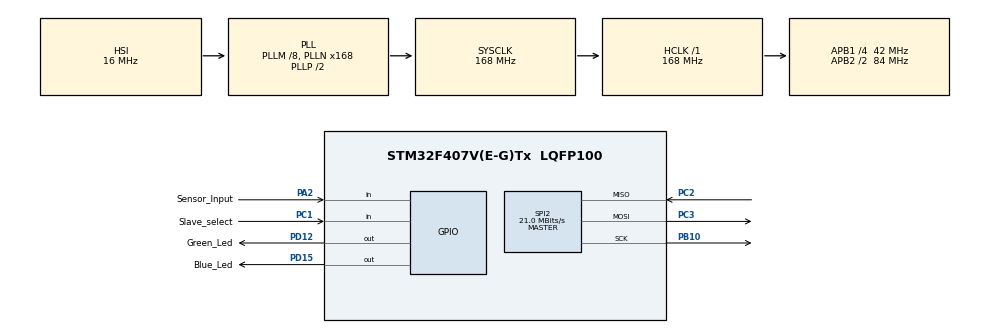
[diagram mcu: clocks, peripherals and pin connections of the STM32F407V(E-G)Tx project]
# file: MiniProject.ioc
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Mcu.Family=STM32F4
Mcu.Name=STM32F407V(E-G)Tx
Mcu.Package=LQFP100
NVIC.PriorityGroup=NVIC_PRIORITYGROUP_0
PA2.GPIO_Label=Sensor_Input
PA2.Signal=GPIO_Input
PB10.Mode=Full_Duplex_Master
PB10.Signal=SPI2_SCK
PC1.GPIO_Label=Slave_select
PC1.Signal=GPIO_Input
PC2.Mode=Full_Duplex_Master
PC2.Signal=SPI2_MISO
PC3.Mode=Full_Duplex_Master
PC3.Signal=SPI2_MOSI
PD12.GPIO_Label=Green_Led
PD12.Signal=GPIO_Output
PD15.GPIO_Label=Blue_Led
PD15.Signal=GPIO_Output
ProjectManager.HeapSize=0x200
ProjectManager.StackSize=0x400
ProjectManager.TargetToolchain=STM32CubeIDE
RCC.48MHZClocksFreq_Value=48000000
RCC.AHBFreq_Value=168000000
RCC.APB1CLKDivider=RCC_HCLK_DIV4
RCC.APB1Freq_Value=42000000
RCC.APB1TimFreq_Value=84000000
RCC.APB2CLKDivider=RCC_HCLK_DIV2
RCC.APB2Freq_Value=84000000
RCC.APB2TimFreq_Value=168000000
RCC.CortexFreq_Value=168000000
RCC.HCLKFreq_Value=168000000
RCC.HSE_VALUE=8000000
RCC.HSI_VALUE=16000000
RCC.PLLM=8
RCC.PLLN=168
RCC.PLLQ=7
RCC.SYSCLKFreq_VALUE=168000000
RCC.SYSCLKSource=RCC_SYSCLKSOURCE_PLLCLK
RCC.VCOOutputFreq_Value=336000000
SPI2.CalculateBaudRate=21.0 MBits/s
SPI2.Direction=SPI_DIRECTION_2LINES
SPI2.Mode=SPI_MODE_MASTER
SPI2.VirtualType=VM_MASTER
board=STM32F407G-DISC1

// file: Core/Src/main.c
/* USER CODE BEGIN Header */
/**
  ******************************************************************************
  * @file           : main.c
  * @brief          : Main program body
  ******************************************************************************
  * @attention
  *
  * <h2><center>&copy; Copyright (c) 2021 STMicroelectronics.
  * All rights reserved.</center></h2>
  *
  * This software component is licensed by ST under Ultimate Liberty license
  * SLA0044, the "License"; You may not use this file except in compliance with
  * the License. You may obtain a copy of the License at:
  *                             www.st.com/SLA0044
  *
  ******************************************************************************
  */
/* USER CODE END Header */
#include "main.h"

/* USER CODE BEGIN Includes */
uint8_t val;
/* USER CODE END Includes */

SPI_HandleTypeDef hspi2;

void SystemClock_Config(void);
static void MX_GPIO_Init(void);
static void MX_SPI2_Init(void);

/* USER CODE BEGIN 0 */
uint8_t val;
/* USER CODE END 0 */

int main(void)
{

  /* MCU Configuration--------------------------------------------------------*/

  /* Reset of all peripherals, Initializes the Flash interface and the Systick. */
  HAL_Init();

  /* Configure the system clock */
  SystemClock_Config();

  /* Initialize all configured peripherals */
  MX_GPIO_Init();
  MX_SPI2_Init();

  /* Infinite loop */
  /* USER CODE BEGIN WHILE */
  while (1)
  {
	val = HAL_GPIO_ReadPin(Sensor_Input_GPIO_Port, Sensor_Input_Pin);
	if(HAL_GPIO_ReadPin(Sensor_Input_GPIO_Port, Sensor_Input_Pin)==1)
	{
	  HAL_GPIO_TogglePin(Green_Led_GPIO_Port, Green_Led_Pin);
	  HAL_Delay(50);
	  while(HAL_GPIO_ReadPin(Sensor_Input_GPIO_Port, Sensor_Input_Pin)==0)
	  {
	    HAL_GPIO_TogglePin(Blue_Led_GPIO_Port, Blue_Led_Pin);
	    HAL_Delay(50);
	  }
	}
	HAL_SPI_Transmit(&hspi2, &val, 10, 100);
	//HAL_Delay(1000);
  }
  /* USER CODE END 3 */
}

void SystemClock_Config(void)
{
  RCC_OscInitTypeDef RCC_OscInitStruct = {0};
  RCC_ClkInitTypeDef RCC_ClkInitStruct = {0};

  /** Configure the main internal regulator output voltage
  */
  __HAL_RCC_PWR_CLK_ENABLE();
  __HAL_PWR_VOLTAGESCALING_CONFIG(PWR_REGULATOR_VOLTAGE_SCALE1);
  /** Initializes the RCC Oscillators according to the specified parameters
  * in the RCC_OscInitTypeDef structure.
  */
  RCC_OscInitStruct.OscillatorType = RCC_OSCILLATORTYPE_HSI;
  RCC_OscInitStruct.HSIState = RCC_HSI_ON;
  RCC_OscInitStruct.HSICalibrationValue = RCC_HSICALIBRATION_DEFAULT;
  RCC_OscInitStruct.PLL.PLLState = RCC_PLL_ON;
  RCC_OscInitStruct.PLL.PLLSource = RCC_PLLSOURCE_HSI;
  RCC_OscInitStruct.PLL.PLLM = 8;
  RCC_OscInitStruct.PLL.PLLN = 168;
  RCC_OscInitStruct.PLL.PLLP = RCC_PLLP_DIV2;
  RCC_OscInitStruct.PLL.PLLQ = 7;
  if (HAL_RCC_OscConfig(&RCC_OscInitStruct) != HAL_OK)
  {
    Error_Handler();
  }
  /** Initializes the CPU, AHB and APB buses clocks
  */
  RCC_ClkInitStruct.ClockType = RCC_CLOCKTYPE_HCLK|RCC_CLOCKTYPE_SYSCLK
                              |RCC_CLOCKTYPE_PCLK1|RCC_CLOCKTYPE_PCLK2;
  RCC_ClkInitStruct.SYSCLKSource = RCC_SYSCLKSOURCE_PLLCLK;
  RCC_ClkInitStruct.AHBCLKDivider = RCC_SYSCLK_DIV1;
  RCC_ClkInitStruct.APB1CLKDivider = RCC_HCLK_DIV4;
  RCC_ClkInitStruct.APB2CLKDivider = RCC_HCLK_DIV2;

  if (HAL_RCC_ClockConfig(&RCC_ClkInitStruct, FLASH_LATENCY_5) != HAL_OK)
  {
    Error_Handler();
  }
}

static void MX_SPI2_Init(void)
{

  /* SPI2 parameter configuration*/
  hspi2.Instance = SPI2;
  hspi2.Init.Mode = SPI_MODE_MASTER;
  hspi2.Init.Direction = SPI_DIRECTION_2LINES;
  hspi2.Init.DataSize = SPI_DATASIZE_8BIT;
  hspi2.Init.CLKPolarity = SPI_POLARITY_LOW;
  hspi2.Init.CLKPhase = SPI_PHASE_1EDGE;
  hspi2.Init.NSS = SPI_NSS_SOFT;
  hspi2.Init.BaudRatePrescaler = SPI_BAUDRATEPRESCALER_2;
  hspi2.Init.FirstBit = SPI_FIRSTBIT_MSB;
  hspi2.Init.TIMode = SPI_TIMODE_DISABLE;
  hspi2.Init.CRCCalculation = SPI_CRCCALCULATION_DISABLE;
  hspi2.Init.CRCPolynomial = 10;
  if (HAL_SPI_Init(&hspi2) != HAL_OK)
  {
    Error_Handler();
  }

}

static void MX_GPIO_Init(void)
{
  GPIO_InitTypeDef GPIO_InitStruct = {0};

  /* GPIO Ports Clock Enable */
  __HAL_RCC_GPIOC_CLK_ENABLE();
  __HAL_RCC_GPIOA_CLK_ENABLE();
  __HAL_RCC_GPIOB_CLK_ENABLE();
  __HAL_RCC_GPIOD_CLK_ENABLE();

  /*Configure GPIO pin Output Level */
  HAL_GPIO_WritePin(GPIOD, Green_Led_Pin|Blue_Led_Pin, GPIO_PIN_RESET);

  /*Configure GPIO pin : Slave_select_Pin */
  GPIO_InitStruct.Pin = Slave_select_Pin;
  GPIO_InitStruct.Mode = GPIO_MODE_INPUT;
  GPIO_InitStruct.Pull = GPIO_NOPULL;
  HAL_GPIO_Init(Slave_select_GPIO_Port, &GPIO_InitStruct);

  /*Configure GPIO pin : Sensor_Input_Pin */
  GPIO_InitStruct.Pin = Sensor_Input_Pin;
  GPIO_InitStruct.Mode = GPIO_MODE_INPUT;
  GPIO_InitStruct.Pull = GPIO_NOPULL;
  HAL_GPIO_Init(Sensor_Input_GPIO_Port, &GPIO_InitStruct);

  /*Configure GPIO pins : Green_Led_Pin Blue_Led_Pin */
  GPIO_InitStruct.Pin = Green_Led_Pin|Blue_Led_Pin;
  GPIO_InitStruct.Mode = GPIO_MODE_OUTPUT_PP;
  GPIO_InitStruct.Pull = GPIO_NOPULL;
  GPIO_InitStruct.Speed = GPIO_SPEED_FREQ_LOW;
  HAL_GPIO_Init(GPIOD, &GPIO_InitStruct);

}

void Error_Handler(void)
{
  __disable_irq();
  while (1)
  {
  }
}

/************************ (C) COPYRIGHT STMicroelectronics *****END OF FILE****/
